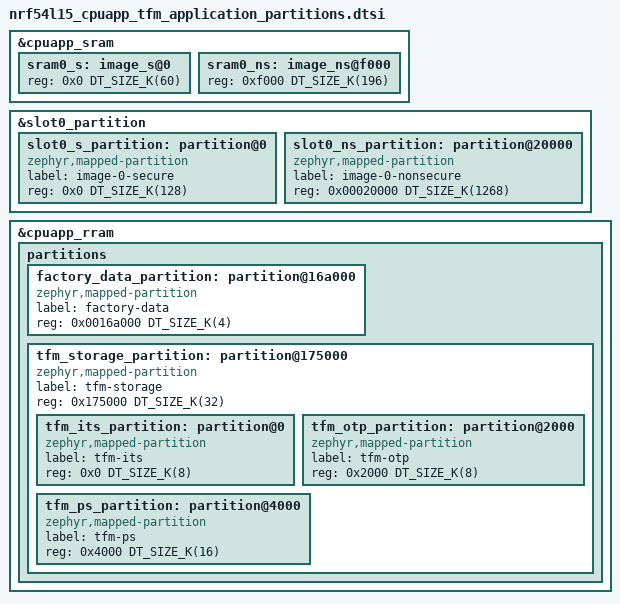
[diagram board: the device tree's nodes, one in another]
/*
 * Copyright (c) 2026 Nordic Semiconductor ASA
 *
 * SPDX-License-Identifier: LicenseRef-Nordic-5-Clause
 */

#include <samples/matter/nrf54l15_cpuapp_tfm_base_partitions.dtsi>

/delete-node/ &sram0_s;
/delete-node/ &sram0_ns;

/* Adjust SRAM for memory-optimized TF-M */

&cpuapp_sram {
	sram0_s: image_s@0 {
		#address-cells = <0x1>;
		#size-cells = <0x1>;
		reg = <0x0 DT_SIZE_K(60)>;
		ranges = <0x0 0x0 DT_SIZE_K(60)>;
	};

	sram0_ns: image_ns@f000 {
		#address-cells = <0x1>;
		#size-cells = <0x1>;
		reg = <0xf000 DT_SIZE_K(196)>;
		ranges = <0x0 0xf000 DT_SIZE_K(196)>;
	};
};

/* Cleanup the default partitioning for Application and TF-M */

/delete-node/ &slot0_ns_partition;
/delete-node/ &tfm_its_partition;
/delete-node/ &tfm_otp_partition;
/delete-node/ &tfm_ps_partition;

/* Specify secure and nonsecure partitions within the slot0_partition which is
 * defined in the tfm_base_partitions file.
 */

&slot0_partition {
	slot0_s_partition: partition@0 {
		compatible = "zephyr,mapped-partition";
		label = "image-0-secure";
		reg = <0x0 DT_SIZE_K(128)>;
	};

	slot0_ns_partition: partition@20000 {
		compatible = "zephyr,mapped-partition";
		label = "image-0-nonsecure";
		reg = <0x00020000 DT_SIZE_K(1268)>;
	};
};

&cpuapp_rram {
	partitions {
		factory_data_partition: partition@16a000 {
			compatible = "zephyr,mapped-partition";
			label = "factory-data";
			reg = <0x0016a000 DT_SIZE_K(4)>;
		};

		tfm_storage_partition: partition@175000 {
			compatible = "zephyr,mapped-partition";
			label = "tfm-storage";
			reg = <0x175000 DT_SIZE_K(32)>;
			ranges = <0x0 0x175000 DT_SIZE_K(32)>;
			#address-cells = <1>;
			#size-cells = <1>;

			tfm_its_partition: partition@0 {
				compatible = "zephyr,mapped-partition";
				label = "tfm-its";
				reg = <0x0 DT_SIZE_K(8)>;
			};

			tfm_otp_partition: partition@2000 {
				compatible = "zephyr,mapped-partition";
				label = "tfm-otp";
				reg = <0x2000 DT_SIZE_K(8)>;
			};

			tfm_ps_partition: partition@4000 {
				compatible = "zephyr,mapped-partition";
				label = "tfm-ps";
				reg = <0x4000 DT_SIZE_K(16)>;
			};
		};
	};
};
